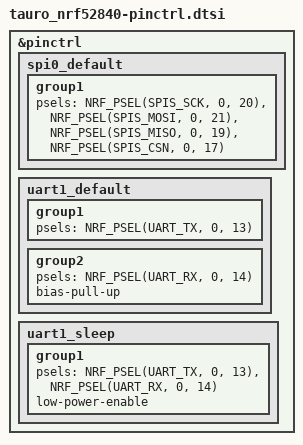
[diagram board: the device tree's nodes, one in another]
/*
 * Copyright (c) 2024 Embeint Holdings Pty Ltd
 * SPDX-License-Identifier: Apache-2.0
 */

&pinctrl {
	spi0_default: spi0_default {
		group1 {
			psels = <NRF_PSEL(SPIS_SCK, 0, 20)>,
				<NRF_PSEL(SPIS_MOSI, 0, 21)>,
				<NRF_PSEL(SPIS_MISO, 0, 19)>,
				<NRF_PSEL(SPIS_CSN, 0, 17)>;
		};
	};

	uart1_default: uart1_default {
		group1 {
			psels = <NRF_PSEL(UART_TX, 0, 13)>;
		};
		group2 {
			psels = <NRF_PSEL(UART_RX, 0, 14)>;
			bias-pull-up;
		};
	};

	uart1_sleep: uart1_sleep {
		group1 {
			psels = <NRF_PSEL(UART_TX, 0, 13)>,
				<NRF_PSEL(UART_RX, 0, 14)>;
			low-power-enable;
		};
	};
};
